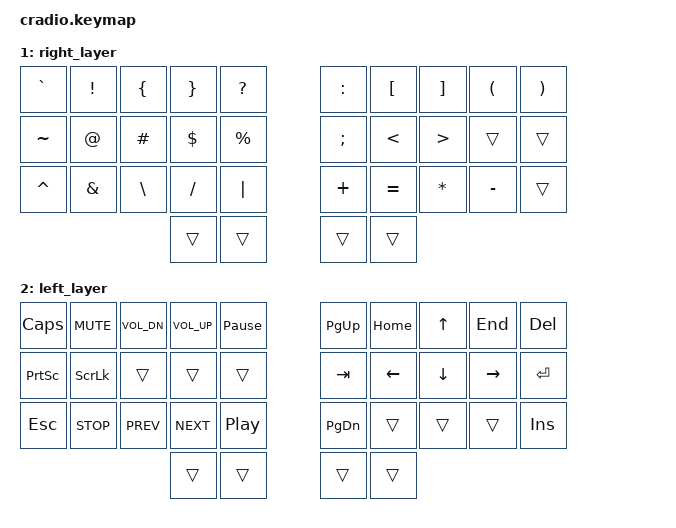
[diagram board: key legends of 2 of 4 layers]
// Copyright (c) 2022 The ZMK Contributors
// SPDX-License-Identifier: MIT

#include <behaviors.dtsi>
#include <dt-bindings/zmk/keys.h>
#include <dt-bindings/zmk/bt.h>

// Home row mods macro
#define HRML(k1,k2,k3,k4) &ht_left LSHFT k1  &ht_left LALT k2  &ht_left LCTRL k3  &ht_left LGUI k4
#define HRMR(k1,k2,k3,k4) &ht_right RGUI k1  &ht_right RCTRL k2  &ht_right RALT k3  &ht_right RSHFT k4

/ {
    behaviors {
        ht: hold_tap {
            compatible = "zmk,behavior-hold-tap";
            #binding-cells = <2>;
            flavor = "balanced";
            tapping-term-ms = <280>;
            quick-tap-ms = <175>;
            require-prior-idle-ms = <150>;
            bindings = <&kp>, <&kp>;
        };
        ht_right: hold_tap_positional_right {
          compatible = "zmk,behavior-hold-tap";
          #binding-cells = <2>;
          flavor = "tap-unless-interrupted";
          tapping-term-ms = <100>;
          require-prior-idle-ms = <100>;
          bindings = <&kp>, <&kp>;
          hold-trigger-key-positions = <0 1 2 3 4 10 11 12 13 14 20 21 22 23 24 30 31>;
        };
        ht_left: hold_tap_positional_left {
          compatible = "zmk,behavior-hold-tap";
          #binding-cells = <2>;
          flavor = "tap-unless-interrupted";
          tapping-term-ms = <100>;
          require-prior-idle-ms = <100>;
          bindings = <&kp>, <&kp>;
          hold-trigger-key-positions = <5 6 7 8 9 15 16 17 18 19 25 26 27 28 29 32 33>;
        };
    };

    conditional_layers {
        compatible = "zmk,conditional-layers";
        tri_layer {
            if-layers = <1 2>;
            then-layer = <3>;
        };
    };

    keymap {
        compatible = "zmk,keymap";
        default_layer {
            bindings = <
        //╭──────────┬──────────┬──────────┬──────────┬──────────╮   ╭──────────┬──────────┬──────────┬──────────┬──────────╮
        //│  Q       │  W       │  F       │  P       │  B       │   │  J       │  L       │  U       │  Y       │  ' "     │
            &kp Q      &kp W      &kp F      &kp P      &kp B          &kp J      &kp L      &kp U      &kp Y      &kp SQT
        //├──────────┼──────────┼──────────┼──────────┼──────────┤   ├──────────┼──────────┼──────────┼──────────┼──────────┤
        //│  A       │  R       │  S       │  T       │  G       │   │  M       │  N       │  E       │  I       │  O       │
            HRML(A,        R,         S,         T)     &kp G          &kp M      HRMR(N,        E,         I,        O)
        //├──────────┼──────────┼──────────┼──────────┼──────────┤   ├──────────┼──────────┼──────────┼──────────┼──────────┤
        //│  Z       │  X       │  C       │  D       │  V       │   │  K       │  H       │ , <      │ . >      │ _        │
            &kp Z      &kp X      &kp C      &kp D      &kp V          &kp K      &kp H      &kp COMMA  &kp DOT    &kp UNDER
        //╰──────────┴──────────┴──────────┼──────────┼──────────┤   ├──────────┼──────────┼──────────┴──────────┴──────────╯
                                            &lt 2 TAB   &kp SPACE  &kp BACKSPACE &lt 1 ENTER
        //                                 ╰──────────┴──────────╯   ╰──────────┴──────────╯
            >;
        };

        right_layer {
            bindings = <
        //╭──────────┬──────────┬──────────┬──────────┬──────────╮   ╭──────────┬──────────┬──────────┬──────────┬──────────╮
        //│ `        │  !       │  {       │  }       │  ?       │   │ :        │ [        │ ]        │  (       │  )       │
           &kp GRAVE  &kp EXCL   &kp LBRC    &kp RBRC   &kp QMARK      &kp COLON  &kp LBKT   &kp RBKT   &kp LPAR   &kp RPAR
        //├──────────┼──────────┼──────────┼──────────┼──────────┤   ├──────────┼──────────┼──────────┼──────────┼──────────┤
        //│ ~        │  @       │  #       │  $       │  %       │   │ ;        │ <        │ >        │          │          │
           &kp TILDE   &kp AT     &kp HASH  &kp DOLLAR  &kp PERCENT    &kp SEMI   &kp LT     &kp GT     &trans     &trans
        //├──────────┼──────────┼──────────┼──────────┼──────────┤   ├──────────┼──────────┼──────────┼──────────┼──────────┤
        //│ ^        │  &       │  \       │  /       │  |       │   │ +        │ =        │ *        │ -        │          │
           &kp CARET   &kp AMPS  &kp BSLH   &kp SLASH   &kp PIPE       &kp PLUS   &kp EQUAL  &kp ASTRK  &kp MINUS  &trans 
        //╰──────────┴──────────┴──────────┼──────────┼──────────┤   ├──────────┼──────────┼──────────┴──────────┴──────────╯
                                             &trans     &trans         &trans     &trans
        //                                 ╰──────────┴──────────╯   ╰──────────┴──────────╯
            >;
        };

        left_layer {
            bindings = <
        //╭──────────┬──────────┬──────────┬──────────┬──────────╮   ╭──────────┬──────────┬──────────┬──────────┬──────────╮
        //│  CAPS    │ MUTE     │ VOL -    │ VOL +    │ PAUSE    │   │ PG UP    │ HOME     │ UP       │ END      │  DELETE  │
     &kp CAPS  &kp K_MUTE &kp K_VOL_DN &kp K_VOL_UP  &kp PAUSE_BREAK   &kp PG_UP   &kp HOME  &kp UP     &kp END   &kp DEL
        //├──────────┼──────────┼──────────┼──────────┼──────────┤   ├──────────┼──────────┼──────────┼──────────┼──────────┤
        //│ PRTSC    │  SCRLK   │          │          │          │   │  TAB     │  LEFT    │  DOWN    │  RIGHT   │  ENTER   │
    &kp PRINTSCREEN   &kp SLCK   &trans     &trans     &trans         &kp TAB    &kp LEFT  &kp DOWN   &kp RIGHT  &kp ENTER
        //├──────────┼──────────┼──────────┼──────────┼──────────┤   ├──────────┼──────────┼──────────┼──────────┼──────────┤
        //│ ESC      │MEDIA STOP│ PREV     │ NEXT     │ PLAY     │   │ PG DOWN  │          │          │          │ INSERT   │
          &kp ESC  &kp C_STOP  &kp C_PREV &kp C_NEXT  &kp C_PP       &kp PG_DN   &trans     &trans     &trans     &kp INS
        //╰──────────┴──────────┴──────────┼──────────┼──────────┤   ├──────────┼──────────┼──────────┴──────────┴──────────╯
                                             &trans     &trans         &trans     &trans
        //                                 ╰──────────┴──────────╯   ╰──────────┴──────────╯
            >;
        };

        // &kp F1      &kp F2     &kp F3     &kp F4     &kp F5         &kp F6     &kp F7     &kp F8     &kp F9     &kp F10 
        tri_layer {
            bindings = <
        //╭──────────┬──────────┬──────────┬──────────┬──────────╮   ╭──────────┬──────────┬──────────┬──────────┬──────────╮
        //│ 1        │ 2        │ 3        │ 4        │ 5        │   │ 6        │ 7        │ 8        │ 9        │ 0        │
           &kp N1      &kp N2     &kp N3     &kp N4     &kp N5         &kp N6     &kp N7     &kp N8     &kp N9     &kp N0 
        //├──────────┼──────────┼──────────┼──────────┼──────────┤   ├──────────┼──────────┼──────────┼──────────┼──────────┤
        //│F1        │ F2       │ F3       │ F4       │ F5       │   │ F6       │ F7       │ F8       │ F9       │ F10      │
            HRML(F1,       F2,      F3,      F4)       &kp F5          &kp F6      HRMR(F7,      F8,      F9,      F10) 
        //├──────────┼──────────┼──────────┼──────────┼──────────┤   ├──────────┼──────────┼──────────┼──────────┼──────────┤
        //│PROFILE 1 │PROFILE 2 │PROFILE 3 │ CLEAR BT │ CTRL     │   │ ALT      │bootloader│  reset   │ F11      │ F12      │
    &bt BT_SEL 0 &bt BT_SEL 1  &bt BT_SEL 2 &bt BT_CLR &sk LCTRL      &sk LALT   &bootloader  &sys_reset &kp F11    &kp F12
        //╰──────────┴──────────┴──────────┼──────────┼──────────┤   ├──────────┼──────────┼──────────┴──────────┴──────────╯
                                             &trans     &trans         &trans     &trans
        //                                 ╰──────────┴──────────╯   ╰──────────┴──────────╯
            >;
        };
    };
};
